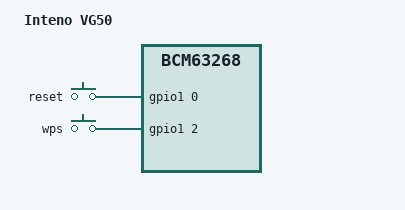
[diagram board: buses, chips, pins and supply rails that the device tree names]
/dts-v1/;

#include "bcm63268.dtsi"

#include <dt-bindings/input/input.h>

/ {
	model = "Inteno VG50";
	compatible = "inteno,vg50", "brcm,bcm63268";

	gpio-keys-polled {
		compatible = "gpio-keys-polled";
		#address-cells = <1>;
		#size-cells = <0>;
		poll-interval = <20>;
		debounce-interval = <60>;

		reset {
			label = "reset";
			gpios = <&gpio1 0 0>;
			linux,code = <KEY_RESTART>;
		};

		wps {
			label = "wps";
			gpios = <&gpio1 2 0>;
			linux,code = <KEY_WPS_BUTTON>;
		};
        };
};
